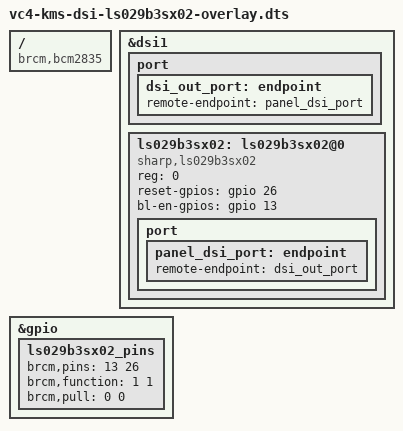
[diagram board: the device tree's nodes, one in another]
/dts-v1/;
/plugin/;

/ {
	compatible = "brcm,bcm2835";

	fragment@0 {
		target = <&dsi1>;
		__overlay__{
			status = "okay";
			#address-cells = <1>;
			#size-cells = <0>;
			port {
				dsi_out_port:endpoint {
					remote-endpoint = <&panel_dsi_port>;
				};
			};

			ls029b3sx02:ls029b3sx02@0 {
				compatible    = "sharp,ls029b3sx02";
				status        = "okay";
				reg           = <0>;
				reset-gpios   = <&gpio 26 0>;   // LCD RST
				bl-en-gpios  = <&gpio 13 0>;    // LCD backlight enable
				port {
					panel_dsi_port: endpoint {
						remote-endpoint = <&dsi_out_port>;
					};
				};
			};
		};
	};

	fragment@1 {
		target = <&gpio>;
		__overlay__ {
			ls029b3sx02_pins: ls029b3sx02_pins {
				brcm,pins = <13 26>;
				brcm,function = <1 1>; // out
				brcm,pull = <0 0>; // off
			};
		};

	};

	__overrides__ {
		reset = <&ls029b3sx02_pins>,"brcm,pins:8",
			<&ls029b3sx02>,"reset-gpios:4";

		bl-en = <&ls029b3sx02_pins>,"brcm,pins:0",
			<&ls029b3sx02>,"bl-en-gpios:4";

	};
};
